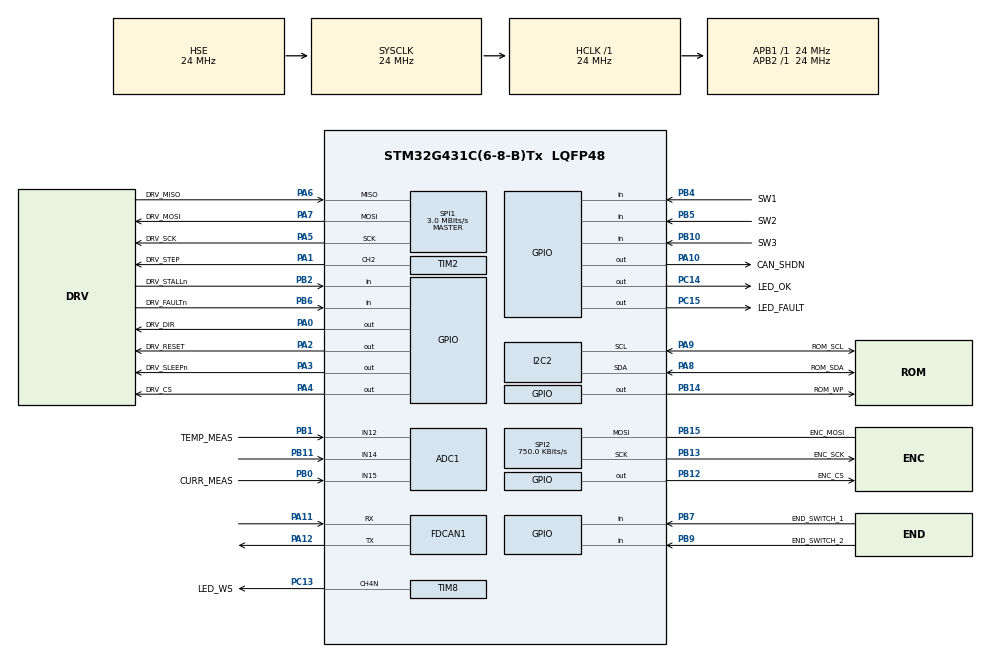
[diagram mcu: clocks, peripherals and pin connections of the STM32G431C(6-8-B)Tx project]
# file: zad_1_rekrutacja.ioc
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ADC1.Channel-0\#ChannelRegularConversion=ADC_CHANNEL_15
ADC1.ClockPrescaler=ADC_CLOCK_SYNC_PCLK_DIV4
ADC1.NbrOfConversionFlag=1
ADC1.OffsetNumber-0\#ChannelRegularConversion=ADC_OFFSET_NONE
ADC1.Rank-0\#ChannelRegularConversion=1
ADC1.SamplingTime-0\#ChannelRegularConversion=ADC_SAMPLETIME_2CYCLES_5
ADC1.master=1
Dma.Request0=TIM8_CH4
Dma.TIM8_CH4.0.Direction=DMA_MEMORY_TO_PERIPH
Dma.TIM8_CH4.0.EventEnable=DISABLE
Dma.TIM8_CH4.0.Instance=DMA1_Channel1
Dma.TIM8_CH4.0.MemDataAlignment=DMA_MDATAALIGN_BYTE
Dma.TIM8_CH4.0.MemInc=DMA_MINC_ENABLE
Dma.TIM8_CH4.0.Mode=DMA_NORMAL
Dma.TIM8_CH4.0.PeriphDataAlignment=DMA_PDATAALIGN_HALFWORD
Dma.TIM8_CH4.0.PeriphInc=DMA_PINC_DISABLE
Dma.TIM8_CH4.0.Polarity=HAL_DMAMUX_REQ_GEN_RISING
Dma.TIM8_CH4.0.Priority=DMA_PRIORITY_LOW
Dma.TIM8_CH4.0.RequestNumber=1
Dma.TIM8_CH4.0.SignalID=NONE
Dma.TIM8_CH4.0.SyncEnable=DISABLE
Dma.TIM8_CH4.0.SyncPolarity=HAL_DMAMUX_SYNC_NO_EVENT
Dma.TIM8_CH4.0.SyncRequestNumber=1
Dma.TIM8_CH4.0.SyncSignalID=NONE
FDCAN1.AutoRetransmission=ENABLE
FDCAN1.CalculateBaudRateNominal=500000
FDCAN1.CalculateTimeBitNominal=2000
FDCAN1.CalculateTimeQuantumNominal=41.666666666666664
FDCAN1.ClockDivider=FDCAN_CLOCK_DIV1
FDCAN1.DataSyncJumpWidth=1
FDCAN1.DataTimeSeg1=5
FDCAN1.DataTimeSeg2=4
FDCAN1.ExtFiltersNbr=1
FDCAN1.FrameFormat=FDCAN_FRAME_CLASSIC
FDCAN1.NominalPrescaler=1
FDCAN1.NominalSyncJumpWidth=12
FDCAN1.NominalTimeSeg1=35
FDCAN1.NominalTimeSeg2=12
FDCAN1.TransmitPause=ENABLE
FREERTOS.Tasks01=defaultTask,24,128,StartDefaultTask,Default,NULL,Dynamic,NULL,NULL;EncoderTask,40,128,StartEncoderTask,Default,NULL,Dynamic,NULL,NULL;StepperRegTask,16,128,StartStepperRegTask,Default,NULL,Dynamic,NULL,NULL;FeedbackTask,8,128,StartFeedbackTask,Default,NULL,Dynamic,NULL,NULL
FREERTOS.configUSE_NEWLIB_REENTRANT=1
I2C2.Timing=0x00805C87
Mcu.Family=STM32G4
Mcu.Name=STM32G431C(6-8-B)Tx
Mcu.Package=LQFP48
NVIC.DMA1_Channel1_IRQn=true\:5\:0\:false\:false\:true\:true\:false\:true\:true
NVIC.FDCAN1_IT0_IRQn=true\:5\:0\:false\:false\:true\:true\:true\:true\:true
NVIC.PriorityGroup=NVIC_PRIORITYGROUP_4
NVIC.TIM1_UP_TIM16_IRQn=true\:5\:0\:false\:false\:true\:false\:false\:true\:true
NVIC.TIM2_IRQn=true\:10\:0\:true\:false\:true\:true\:true\:true\:true
NVIC.TIM6_DAC_IRQn=true\:15\:0\:true\:false\:true\:true\:true\:true\:true
NVIC.TimeBase=TIM1_UP_TIM16_IRQn
NVIC.TimeBaseIP=TIM1
PA0.GPIO_Label=DRV_DIR
PA0.Signal=GPIO_Output
PA1.GPIO_Label=DRV_STEP
PA1.Signal=S_TIM2_CH2
PA10.GPIO_Label=CAN_SHDN
PA10.Signal=GPIO_Output
PA11.GPIO_Speed=GPIO_SPEED_FREQ_VERY_HIGH
PA11.Mode=FDCAN_Activate
PA11.Signal=FDCAN1_RX
PA12.GPIO_Speed=GPIO_SPEED_FREQ_VERY_HIGH
PA12.Mode=FDCAN_Activate
PA12.Signal=FDCAN1_TX
PA13.Mode=JTAG_4_pins
PA13.Signal=SYS_JTMS-SWDIO
PA14.Mode=JTAG_4_pins
PA14.Signal=SYS_JTCK-SWCLK
PA15.Mode=JTAG_4_pins
PA15.Signal=SYS_JTDI
PA2.GPIO_Label=DRV_RESET
PA2.Signal=GPIO_Output
PA3.GPIO_Label=DRV_SLEEPn
PA3.PinState=GPIO_PIN_RESET
PA3.Signal=GPIO_Output
PA4.GPIO_Label=DRV_CS
PA4.Signal=GPIO_Output
PA5.GPIO_Label=DRV_SCK
PA5.Mode=Full_Duplex_Master
PA5.Signal=SPI1_SCK
PA6.GPIO_Label=DRV_MISO
PA6.Mode=Full_Duplex_Master
PA6.Signal=SPI1_MISO
PA7.GPIO_Label=DRV_MOSI
PA7.Mode=Full_Duplex_Master
PA7.Signal=SPI1_MOSI
PA8.GPIO_Label=ROM_SDA
PA8.GPIO_Pu=GPIO_PULLUP
PA8.Mode=I2C
PA8.Signal=I2C2_SDA
PA9.GPIO_Label=ROM_SCL
PA9.GPIO_Pu=GPIO_PULLUP
PA9.Mode=I2C
PA9.Signal=I2C2_SCL
PB0.GPIO_Label=CURR_MEAS
PB0.Mode=IN15-Single-Ended
PB0.Signal=ADC1_IN15
PB1.GPIO_Label=TEMP_MEAS
PB1.Mode=IN12-Single-Ended
PB1.Signal=ADC1_IN12
PB10.GPIO_Label=SW3
PB10.GPIO_PuPd=GPIO_PULLUP
PB10.Signal=GPIO_Input
PB11.Mode=IN14-Single-Ended
PB11.Signal=ADC1_IN14
PB12.GPIO_Label=ENC_CS
PB12.Signal=GPIO_Output
PB13.GPIO_Label=ENC_SCK
PB13.Mode=Simplex_Bidirectional_Master
PB13.Signal=SPI2_SCK
PB14.GPIO_Label=ROM_WP
PB14.GPIO_Speed=GPIO_SPEED_FREQ_MEDIUM
PB14.PinState=GPIO_PIN_SET
PB14.Signal=GPIO_Output
PB15.GPIO_Label=ENC_MOSI
PB15.Mode=Simplex_Bidirectional_Master
PB15.Signal=SPI2_MOSI
PB2.GPIO_Label=DRV_STALLn
PB2.Signal=GPIO_Input
PB3.Mode=JTAG_4_pins
PB3.Signal=SYS_JTDO-SWO
PB4.GPIO_Label=SW1
PB4.GPIO_PuPd=GPIO_PULLUP
PB4.Signal=GPIO_Input
PB5.GPIO_Label=SW2
PB5.GPIO_PuPd=GPIO_PULLUP
PB5.Signal=GPIO_Input
PB6.GPIO_Label=DRV_FAULTn
PB6.GPIO_PuPd=GPIO_NOPULL
PB6.Signal=GPIO_Input
PB7.GPIO_Label=END_SWITCH_1
PB7.GPIO_PuPd=GPIO_PULLUP
PB7.Signal=GPIO_Input
PB9.GPIO_Label=END_SWITCH_2
PB9.GPIO_PuPd=GPIO_PULLUP
PB9.Signal=GPIO_Input
PC13.GPIO_Label=LED_WS
PC13.Mode=PWM Generation4 CH4N
PC13.Signal=TIM8_CH4N
PC14-OSC32_IN.GPIO_Label=LED_OK
PC14-OSC32_IN.GPIO_ModeDefaultOutputPP=GPIO_MODE_OUTPUT_PP
PC14-OSC32_IN.GPIO_PuPd=GPIO_NOPULL
PC14-OSC32_IN.PinState=GPIO_PIN_SET
PC14-OSC32_IN.Signal=GPIO_Output
PC15-OSC32_OUT.GPIO_Label=LED_FAULT
PC15-OSC32_OUT.GPIO_ModeDefaultOutputPP=GPIO_MODE_OUTPUT_PP
PC15-OSC32_OUT.GPIO_PuPd=GPIO_NOPULL
PC15-OSC32_OUT.PinState=GPIO_PIN_SET
PC15-OSC32_OUT.Signal=GPIO_Output
PF0-OSC_IN.Mode=HSE-External-Oscillator
PF0-OSC_IN.Signal=RCC_OSC_IN
PF1-OSC_OUT.Mode=HSE-External-Oscillator
PF1-OSC_OUT.Signal=RCC_OSC_OUT
ProjectManager.HeapSize=0x200
ProjectManager.StackSize=0x400
ProjectManager.TargetToolchain=STM32CubeIDE
RCC.ADC12Freq_Value=24000000
RCC.AHBFreq_Value=24000000
RCC.APB1Freq_Value=24000000
RCC.APB1TimFreq_Value=24000000
RCC.APB2Freq_Value=24000000
RCC.APB2TimFreq_Value=24000000
RCC.CortexFreq_Value=24000000
RCC.EXTERNAL_CLOCK_VALUE=12288000
RCC.HCLKFreq_Value=24000000
RCC.HSE_VALUE=24000000
RCC.HSI48_VALUE=48000000
RCC.HSI_VALUE=16000000
RCC.LSE_VALUE=32768
RCC.PLLSourceVirtual=RCC_PLLSOURCE_HSE
RCC.SYSCLKFreq_VALUE=24000000
RCC.SYSCLKSource=RCC_SYSCLKSOURCE_HSE
RCC.USBFreq_Value=96000000
RCC.VCOOutputFreq_Value=192000000
SH.S_TIM2_CH2.0=TIM2_CH2,PWM Generation2 CH2
SPI1.BaudRatePrescaler=SPI_BAUDRATEPRESCALER_8
SPI1.CalculateBaudRate=3.0 MBits/s
SPI1.DataSize=SPI_DATASIZE_16BIT
SPI1.Direction=SPI_DIRECTION_2LINES
SPI1.Mode=SPI_MODE_MASTER
SPI1.VirtualType=VM_MASTER
SPI2.BaudRatePrescaler=SPI_BAUDRATEPRESCALER_32
SPI2.CLKPhase=SPI_PHASE_2EDGE
SPI2.CalculateBaudRate=750.0 KBits/s
SPI2.DataSize=SPI_DATASIZE_8BIT
SPI2.Direction=SPI_DIRECTION_1LINE
SPI2.Mode=SPI_MODE_MASTER
SPI2.VirtualType=VM_MASTER
TIM2.Channel-PWM\ Generation2\ CH2=TIM_CHANNEL_2
TIM2.PeriodNoDither=3749
TIM2.Prescaler=0
TIM2.PulseNoDither_2=374
TIM6.PeriodNoDither=2399
TIM6.TIM_MasterOutputTrigger=TIM_TRGO_RESET
TIM8.Channel-PWM\ Generation4\ CH4N=TIM_CHANNEL_4
TIM8.PeriodNoDither=30
VP_FREERTOS_VS_CMSIS_V2.Mode=CMSIS_V2
VP_SYS_VS_DBSignals.Mode=DisableDeadBatterySignals
VP_SYS_VS_tim1.Mode=TIM1
VP_TIM2_VS_ClockSourceINT.Mode=Internal
VP_TIM6_VS_ClockSourceINT.Mode=Enable_Timer
VP_TIM8_VS_ClockSourceINT.Mode=Internal
board=custom

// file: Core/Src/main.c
/* USER CODE BEGIN Header */
/**
  ******************************************************************************
  * @file           : main.c
  * @brief          : Main program body
  ******************************************************************************
  * @attention
  *
  * Copyright (c) 2024 STMicroelectronics.
  * All rights reserved.
  *
  * This software is licensed under terms that can be found in the LICENSE file
  * in the root directory of this software component.
  * If no LICENSE file comes with this software, it is provided AS-IS.
  *
  ******************************************************************************
  */
/* USER CODE END Header */
#include "main.h"
#include "cmsis_os.h"
#include "adc.h"
#include "dma.h"
#include "fdcan.h"
#include "i2c.h"
#include "spi.h"
#include "tim.h"
#include "gpio.h"

/* USER CODE BEGIN Includes */
#include "DRV_8711.h"
/* USER CODE END Includes */

void SystemClock_Config(void);
void MX_FREERTOS_Init(void);

int main(void)
{

  /* MCU Configuration--------------------------------------------------------*/

  /* Reset of all peripherals, Initializes the Flash interface and the Systick. */
  HAL_Init();

  /* Configure the system clock */
  SystemClock_Config();

  /* Initialize all configured peripherals */
  MX_GPIO_Init();
  MX_DMA_Init();
  MX_FDCAN1_Init();
  MX_I2C2_Init();
  MX_SPI1_Init();
  MX_SPI2_Init();
  MX_TIM8_Init();
  MX_ADC1_Init();
  MX_TIM6_Init();
  MX_TIM2_Init();
  /* USER CODE BEGIN 2 */

  HAL_TIM_Base_Start_IT(&htim2);
  HAL_TIM_PWM_Start(&htim2, TIM_CHANNEL_2);

  HAL_GPIO_TogglePin(DRV_SLEEPn_GPIO_Port, DRV_SLEEPn_Pin);
  HAL_GPIO_TogglePin(DRV_RESET_GPIO_Port,DRV_RESET_Pin );
  HAL_Delay(500);
  HAL_GPIO_TogglePin(DRV_RESET_GPIO_Port,DRV_RESET_Pin);

  drv_reg_write(CTRL,CTRL_set);
  drv_reg_write(TORQUE,TORQUE_set);
  drv_reg_write(BLANK,BLANK_set );
  /*kierunek*/
  HAL_GPIO_WritePin(DRV_DIR_GPIO_Port, DRV_DIR_Pin, GPIO_PIN_RESET);

  /* USER CODE END 2 */

  /* Init scheduler */
  osKernelInitialize();

  /* Call init function for freertos objects (in cmsis_os2.c) */
  MX_FREERTOS_Init();

  /* Start scheduler */
  osKernelStart();

  /* We should never get here as control is now taken by the scheduler */

  /* Infinite loop */
  while (1)
  {

  }
}

void SystemClock_Config(void)
{
  RCC_OscInitTypeDef RCC_OscInitStruct = {0};
  RCC_ClkInitTypeDef RCC_ClkInitStruct = {0};

  /** Configure the main internal regulator output voltage
  */
  HAL_PWREx_ControlVoltageScaling(PWR_REGULATOR_VOLTAGE_SCALE1);

  /** Initializes the RCC Oscillators according to the specified parameters
  * in the RCC_OscInitTypeDef structure.
  */
  RCC_OscInitStruct.OscillatorType = RCC_OSCILLATORTYPE_HSE;
  RCC_OscInitStruct.HSEState = RCC_HSE_ON;
  RCC_OscInitStruct.PLL.PLLState = RCC_PLL_NONE;
  if (HAL_RCC_OscConfig(&RCC_OscInitStruct) != HAL_OK)
  {
    Error_Handler();
  }

  /** Initializes the CPU, AHB and APB buses clocks
  */
  RCC_ClkInitStruct.ClockType = RCC_CLOCKTYPE_HCLK|RCC_CLOCKTYPE_SYSCLK
                              |RCC_CLOCKTYPE_PCLK1|RCC_CLOCKTYPE_PCLK2;
  RCC_ClkInitStruct.SYSCLKSource = RCC_SYSCLKSOURCE_HSE;
  RCC_ClkInitStruct.AHBCLKDivider = RCC_SYSCLK_DIV1;
  RCC_ClkInitStruct.APB1CLKDivider = RCC_HCLK_DIV1;
  RCC_ClkInitStruct.APB2CLKDivider = RCC_HCLK_DIV1;

  if (HAL_RCC_ClockConfig(&RCC_ClkInitStruct, FLASH_LATENCY_0) != HAL_OK)
  {
    Error_Handler();
  }
}

void HAL_TIM_PeriodElapsedCallback(TIM_HandleTypeDef *htim)
{
  if (htim->Instance == TIM1) {
    HAL_IncTick();
  }
}

void Error_Handler(void)
{
  __disable_irq();
  while (1)
  {
  }
}
